AUTOSAR XML (schema 314)
package /ComponentType
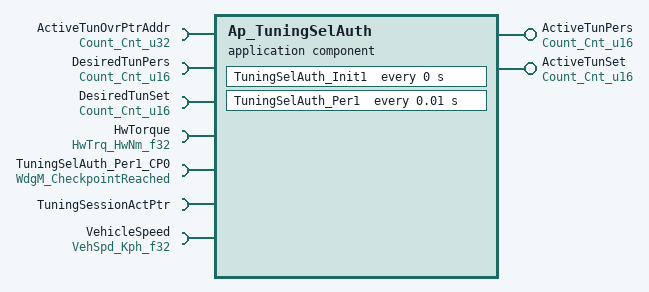
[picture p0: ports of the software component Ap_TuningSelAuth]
  application software component type Ap_TuningSelAuth
    provide port ActiveTunPers: unqueued-sender-com-spec{data-element=Cnt_u16, can-invalidate=false, init-value=D_ZERO_CNT_U16}, provided-interface=Count_Cnt_u16
    provide port ActiveTunSet: unqueued-sender-com-spec{data-element=Cnt_u16, can-invalidate=false, init-value=D_ZERO_CNT_U16}, provided-interface=Count_Cnt_u16
    7 x require port:
      ActiveTunOvrPtrAddr: unqueued-receiver-com-spec{data-element=Cnt_u32, init-value=D_ZERO_CNT_U32}, required-interface=Count_Cnt_u32
      DesiredTunPers: unqueued-receiver-com-spec{data-element=Cnt_u16, init-value=D_ZERO_CNT_U16}, required-interface=Count_Cnt_u16
      DesiredTunSet: unqueued-receiver-com-spec{data-element=Cnt_u16, init-value=D_ZERO_CNT_U16}, required-interface=Count_Cnt_u16
      HwTorque: unqueued-receiver-com-spec{data-element=HwNm_f32, init-value=D_ZERO_ULS_F32}, required-interface=HwTrq_HwNm_f32
      TuningSelAuth_Per1_CP0: client-com-spec=CheckpointReached, required-interface=WdgM_CheckpointReached
      TuningSessionActPtr: unqueued-receiver-com-spec{data-element=Cnt_u8, init-value=C_INIT_TUNINGSESSIONADDRPTRENUM}, required-interface=TuningSessionActPtr
      VehicleSpeed: unqueued-receiver-com-spec{data-element=Kph_f32, init-value=D_ZERO_ULS_F32}, required-interface=VehSpd_Kph_f32
  internal behavior Ap_TuningSelAuth_InternalBehavior: component=Ap_TuningSelAuth
    timing event TuningSelAuth_Init1_InitEvent: start-on-event=TuningSelAuth_Init1, period=0
    timing event TMT_TuningSelAuth_Per1: start-on-event=TuningSelAuth_Per1, period=0.01
    port-api-options:
      enable-take-address=false, indirect-api=false, port=ActiveTunOvrPtrAddr
      enable-take-address=false, indirect-api=false, port=ActiveTunPers
      enable-take-address=false, indirect-api=false, port=ActiveTunSet
      enable-take-address=false, indirect-api=false, port=DesiredTunPers
      enable-take-address=false, indirect-api=false, port=DesiredTunSet
      enable-take-address=false, indirect-api=false, port=HwTorque
      enable-take-address=false, indirect-api=false, port=TuningSelAuth_Per1_CP0
      enable-take-address=false, indirect-api=false, port=TuningSessionActPtr
      enable-take-address=false, indirect-api=false, port=VehicleSpeed
    runnable TuningSelAuth_Init1
      data read access READ_DesiredTunPers_Cnt_u16: data-element=DesiredTunPers.Cnt_u16
      data read access READ_DesiredTunSet_Cnt_u16: data-element=DesiredTunSet.Cnt_u16
      data write access WRITE_ActiveTunPers_Cnt_u16: data-element=ActiveTunPers.Cnt_u16
      data write access WRITE_ActiveTunSet_Cnt_u16: data-element=ActiveTunSet.Cnt_u16
    runnable TuningSelAuth_Per1
      6 x data read access:
        READ_ActiveTunOvrPtrAddr_Cnt_u32: data-element=ActiveTunOvrPtrAddr.Cnt_u32
        READ_DesiredTunPers_Cnt_u16: data-element=DesiredTunPers.Cnt_u16
        READ_DesiredTunSet_Cnt_u16: data-element=DesiredTunSet.Cnt_u16
        READ_HwTorque_HwNm_f32: data-element=HwTorque.HwNm_f32
        READ_TuningSessionActPtr_Cnt_u8: data-element=TuningSessionActPtr.Cnt_u8
        READ_VehicleSpeed_Kph_f32: data-element=VehicleSpeed.Kph_f32
      data write access WRITE_ActiveTunPers_Cnt_u16: data-element=ActiveTunPers.Cnt_u16
      data write access WRITE_ActiveTunSet_Cnt_u16: data-element=ActiveTunSet.Cnt_u16
      sync call SC_TuningSelAuth_Per1_CP0_CheckpointReached: operation=TuningSelAuth_Per1_CP0.CheckpointReached, timeout=0
  swc implementation Ap_TuningSelAuth_Implementation: behavior=Ap_TuningSelAuth_InternalBehavior
    code-descriptors:
      code Code: type=SRC
